# MDR32F8 register map
Vendor: Milandr; File version: 1.0
CPU: CM4 r1p1, little endian, no MPU, no FPU, 3 interrupt priority bits
Registers are 32-bit, read-write, reset 0x0 unless marked. A register's access mark holds for its fields unless they carry their own. Offsets are from the block's base; [hi:lo] are bit positions; {n}, {i} and the like mark numbered series.

## DAC0 — DAC
Base 0x400AC000
Same registers: DAC1 0x400AD000
0x00 KEY — Key lock Register
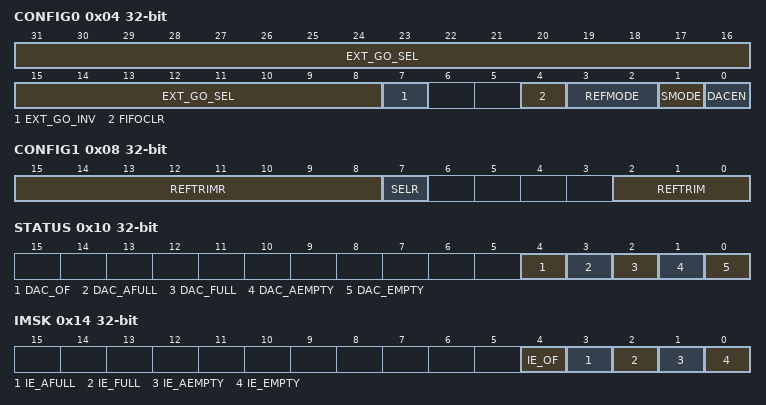
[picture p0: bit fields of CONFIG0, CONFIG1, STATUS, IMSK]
0x04 CONFIG0 — DAC Configuration Register
  [31:8] EXT_GO_SEL, [7] EXT_GO_INV, [4] FIFOCLR, [3:2] REFMODE, [1] SMODE, [0] DACEN
0x08 CONFIG1 — DAC Configuration Register
  [15:8] REFTRIMR, [7] SELR, [2:0] REFTRIM
0x0C DATA — DAC Data Register
  [11:0] DATA
0x10 STATUS ro — DAC Status Register
  [4] DAC_OF rw, [3] DAC_AFULL, [2] DAC_FULL, [1] DAC_AEMPTY, [0] DAC_EMPTY
0x14 IMSK — DAC inerrupt Register
  [4] IE_OF, [3] IE_AFULL, [2] IE_FULL, [1] IE_AEMPTY, [0] IE_EMPTY
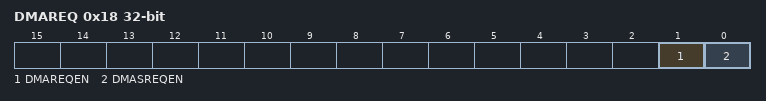
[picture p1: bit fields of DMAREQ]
0x18 DMAREQ — DAC DMA Request Register
  [1] DMAREQEN, [0] DMASREQEN

## MDR_ETH — Ethernet
Base 0x21000000
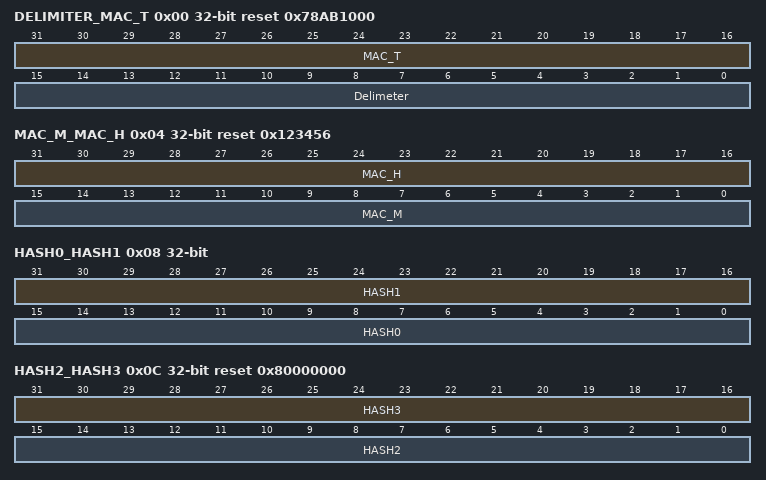
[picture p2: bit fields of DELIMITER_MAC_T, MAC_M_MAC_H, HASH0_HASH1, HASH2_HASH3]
0x00 DELIMITER_MAC_T reset 0x78AB1000
  [31:16] MAC_T, [15:0] Delimeter
0x04 MAC_M_MAC_H reset 0x123456
  [31:16] MAC_H, [15:0] MAC_M
0x08 HASH0_HASH1
  [31:16] HASH1, [15:0] HASH0
0x0C HASH2_HASH3 reset 0x80000000
  [31:16] HASH3, [15:0] HASH2
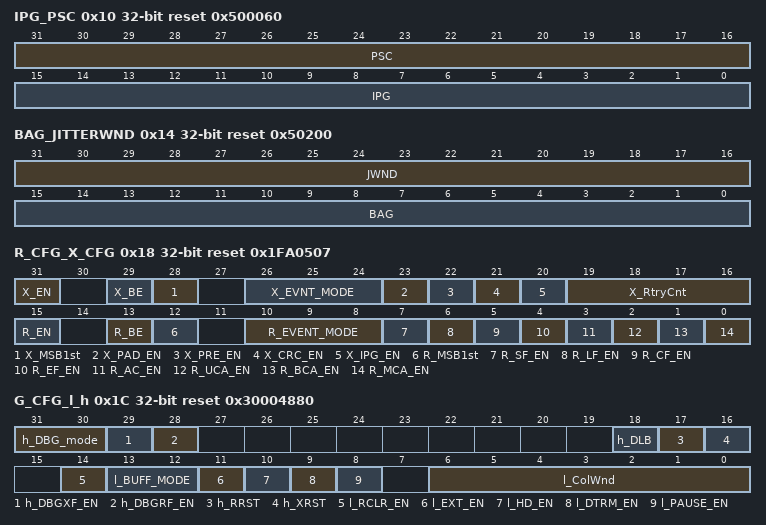
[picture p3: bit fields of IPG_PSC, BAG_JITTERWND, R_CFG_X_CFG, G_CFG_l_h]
0x10 IPG_PSC reset 0x500060
  [31:16] PSC, [15:0] IPG
0x14 BAG_JITTERWND reset 0x50200
  [31:16] JWND, [15:0] BAG
0x18 R_CFG_X_CFG reset 0x1FA0507
  [31] X_EN, [29] X_BE, [28] X_MSB1st, [26:24] X_EVNT_MODE, [23] X_PAD_EN, [22] X_PRE_EN, [21] X_CRC_EN, [20] X_IPG_EN, [19:16] X_RtryCnt, [15] R_EN, [13] R_BE, [12] R_MSB1st, [10:8] R_EVENT_MODE, [7] R_SF_EN, [6] R_LF_EN, [5] R_CF_EN, [4] R_EF_EN, [3] R_AC_EN, [2] R_UCA_EN, [1] R_BCA_EN, [0] R_MCA_EN
0x1C G_CFG_l_h reset 0x30004880
  [31:30] h_DBG_mode, [29] h_DBGXF_EN, [28] h_DBGRF_EN, [18] h_DLB, [17] h_RRST, [16] h_XRST, [14] l_RCLR_EN, [13:12] l_BUFF_MODE, [11] l_EXT_EN, [10] l_HD_EN, [9] l_DTRM_EN, [8] l_PAUSE_EN, [6:0] l_ColWnd
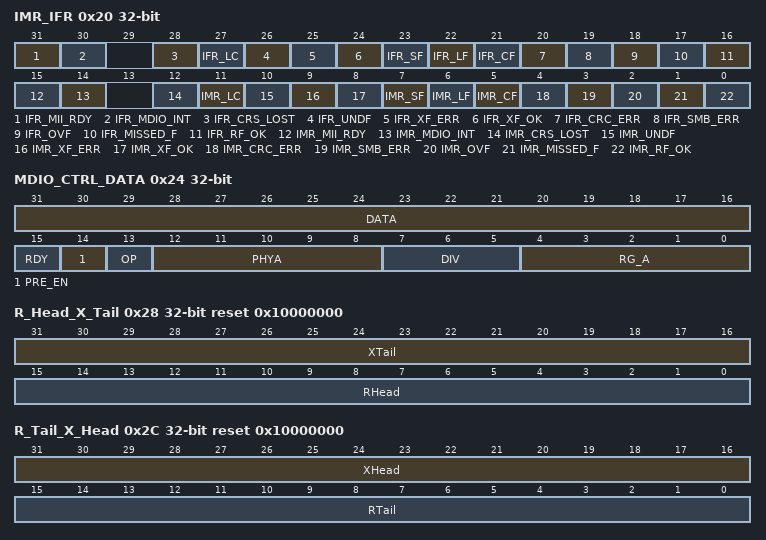
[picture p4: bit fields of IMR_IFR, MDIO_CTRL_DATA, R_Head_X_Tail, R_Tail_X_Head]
0x20 IMR_IFR
  [31] IFR_MII_RDY, [30] IFR_MDIO_INT, [28] IFR_CRS_LOST, [27] IFR_LC, [26] IFR_UNDF, [25] IFR_XF_ERR, [24] IFR_XF_OK, [23] IFR_SF, [22] IFR_LF, [21] IFR_CF, [20] IFR_CRC_ERR, [19] IFR_SMB_ERR, [18] IFR_OVF, [17] IFR_MISSED_F, [16] IFR_RF_OK, [15] IMR_MII_RDY, [14] IMR_MDIO_INT, [12] IMR_CRS_LOST, [11] IMR_LC, [10] IMR_UNDF, [9] IMR_XF_ERR, [8] IMR_XF_OK, [7] IMR_SF, [6] IMR_LF, [5] IMR_CF, [4] IMR_CRC_ERR, [3] IMR_SMB_ERR, [2] IMR_OVF, [1] IMR_MISSED_F, [0] IMR_RF_OK
0x24 MDIO_CTRL_DATA
  [31:16] DATA, [15] RDY, [14] PRE_EN, [13] OP, [12:8] PHYA, [7:5] DIV, [4:0] RG_A
0x28 R_Head_X_Tail reset 0x10000000
  [31:16] XTail, [15:0] RHead
0x2C R_Tail_X_Head ro reset 0x10000000
  [31:16] XHead, [15:0] RTail
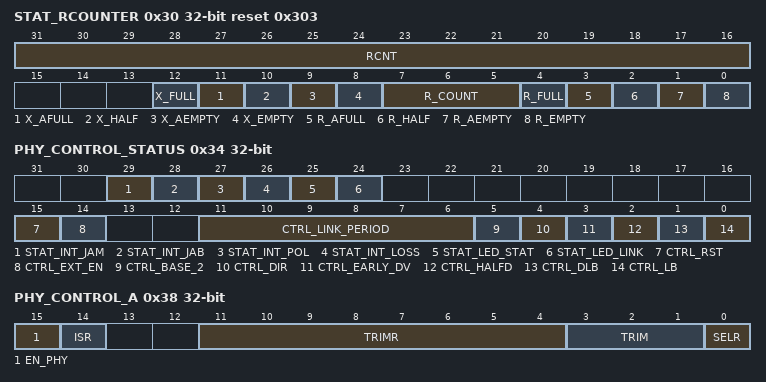
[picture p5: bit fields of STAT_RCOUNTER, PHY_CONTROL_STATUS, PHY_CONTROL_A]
0x30 STAT_RCOUNTER ro reset 0x303
  [31:16] RCNT, [12] X_FULL, [11] X_AFULL, [10] X_HALF, [9] X_AEMPTY, [8] X_EMPTY, [7:5] R_COUNT, [4] R_FULL, [3] R_AFULL, [2] R_HALF, [1] R_AEMPTY, [0] R_EMPTY
0x34 PHY_CONTROL_STATUS
  [29] STAT_INT_JAM ro, [28] STAT_INT_JAB ro, [27] STAT_INT_POL ro, [26] STAT_INT_LOSS ro, [25] STAT_LED_STAT ro, [24] STAT_LED_LINK ro, [15] CTRL_RST, [14] CTRL_EXT_EN, [11:6] CTRL_LINK_PERIOD, [5] CTRL_BASE_2, [4] CTRL_DIR, [3] CTRL_EARLY_DV, [2] CTRL_HALFD, [1] CTRL_DLB, [0] CTRL_LB
0x38 PHY_CONTROL_A
  [15] EN_PHY, [14] ISR, [11:4] TRIMR, [3:1] TRIM, [0] SELR

## MDR_DMA — DMA controller registers
Base 0xE0042000
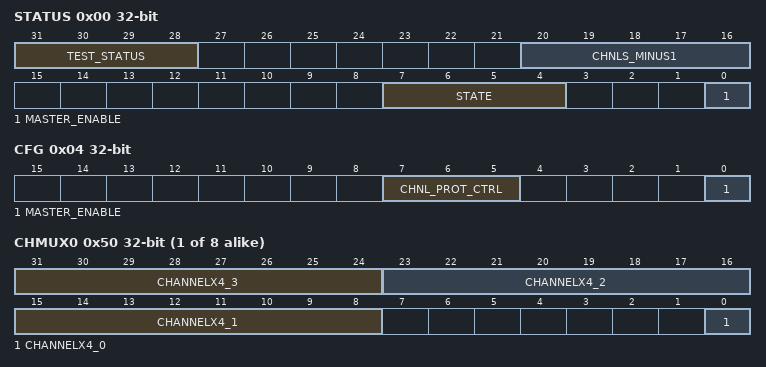
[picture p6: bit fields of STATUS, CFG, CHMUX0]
0x00 STATUS ro — DMA Status Register
  [31:28] TEST_STATUS, [20:16] CHNLS_MINUS1, [7:4] STATE, [0] MASTER_ENABLE
0x04 CFG wo — DMA Configuration Register
  [7:5] CHNL_PROT_CTRL, [0] MASTER_ENABLE
0x08 CTRL_BASE_PTR
  [31:10] CTRL_BASE_PTR
0x0C ALT_CTRL_BASE_PTR ro
0x10 WAITONREQ_STATUS ro
0x14 CHNL_SW_REQUEST wo
0x18 CHNL_USEBURST_SET
0x1C CHNL_USEBURST_CLR wo
0x20 CHNL_REQ_MASK_SET
0x24 CHNL_REQ_MASK_CLR wo
0x28 CHNL_ENABLE_SET
0x2C CHNL_ENABLE_CLR wo
0x30 CHNL_PRI_ALT_SET
0x34 CHNL_PRI_ALT_CLR wo
0x38 CHNL_PRIORITY_SET
0x3C CHNL_PRIORITY_CLR wo
0x4C ERR_CLR
  [0] ERR_CLR
{0x50+4i} CHMUX{i} (i=0..7)
  [31:24] CHANNELX4_3, [23:16] CHANNELX4_2, [15:8] CHANNELX4_1, [0] CHANNELX4_0
